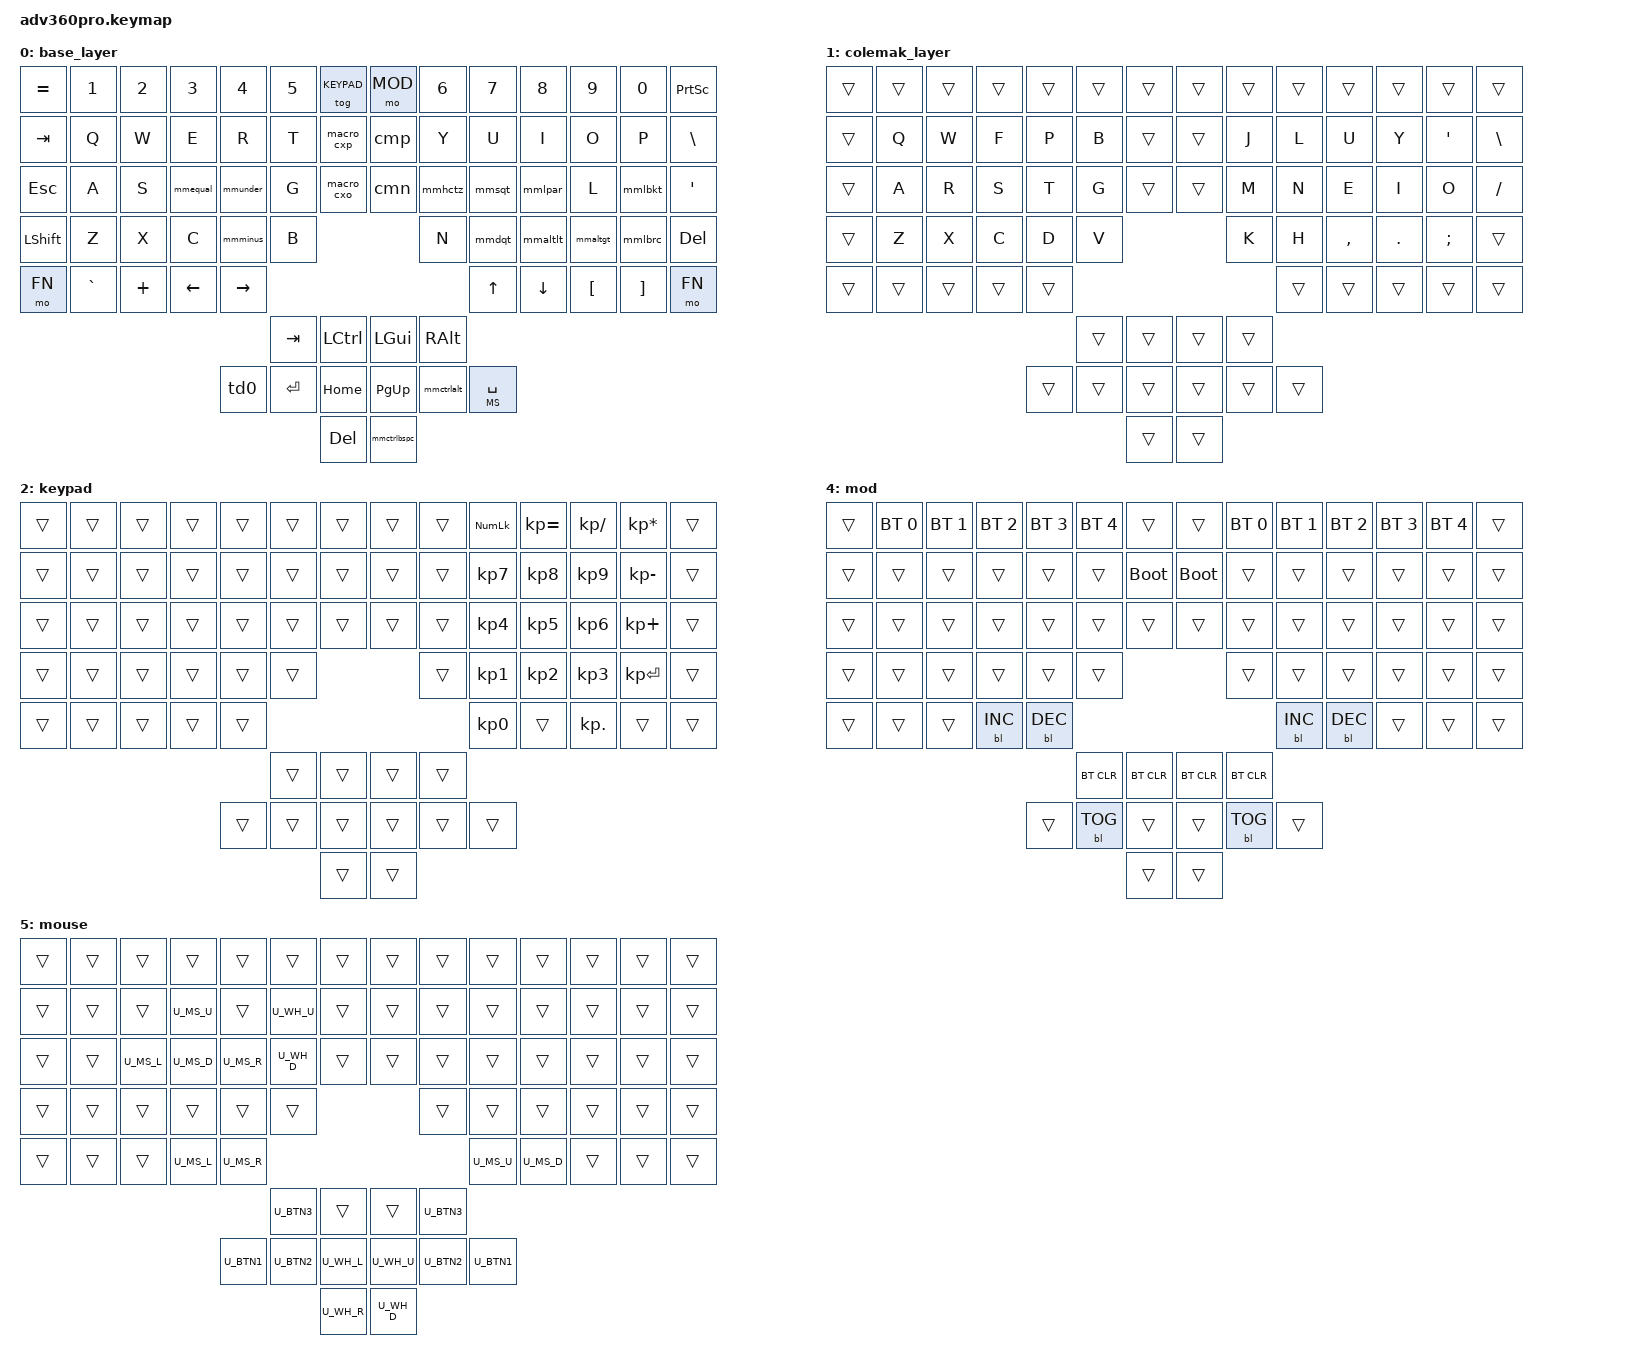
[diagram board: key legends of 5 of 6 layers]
#include <behaviors.dtsi>
#include <dt-bindings/zmk/keys.h>
#include <dt-bindings/zmk/bt.h>
#include <dt-bindings/zmk/outputs.h>
#include <dt-bindings/zmk/rgb.h>
#include <dt-bindings/zmk/backlight.h>

/* definitions for mouse layer */
#include "mouse.dtsi"

#define ___ &trans

#define QWERTY 0
#define COLEMAK 1
#define KEYPAD 2
#define FN 3
#define MOD 4
#define MS 5

#define MOD_MORPH_C(NAME, KEY, MOD_KEY) \
  mm##NAME: mm##NAME { \
    compatible = "zmk,behavior-mod-morph"; \
    label = #NAME; \
    #binding-cells = <0>; \
    bindings = <&kp KEY>, <&kp MOD_KEY>; \
    mods = <(MOD_LCTL|MOD_RCTL)>; \
  };

#define MOD_MORPH_S(NAME, KEY, MOD_KEY) \
  mm##NAME: mm##NAME { \
    compatible = "zmk,behavior-mod-morph"; \
    label = #NAME; \
    #binding-cells = <0>; \
    bindings = <&kp KEY>, <&kp MOD_KEY>; \
    mods = <(MOD_LSFT|MOD_RSFT)>; \
  };


/ {
      behaviors {
      #include "macros.dtsi"

      ht: hold_toggle {
	  compatible = "zmk,behavior-hold-tap";
	  label = "HOLD_TOGGLE";
          #binding-cells = <2>;
	  tapping-term-ms = <200>;
	  quick_tap_ms = <175>;
	  flavor = "tap-preferred";
	  bindings = <&mo>, <&kp>;
	};

        MOD_MORPH_S(ctrlbspc, BSPC, LC(BSPC))
	MOD_MORPH_S(ctrlalt, RCTL, LALT)
	MOD_MORPH_C(equal, D, EQUAL)
	MOD_MORPH_C(under, F, UNDERSCORE)
	MOD_MORPH_C(minus, V, MINUS)
	MOD_MORPH_C(sqt, J, SQT)
	MOD_MORPH_C(lpar, K, LPAR)
	MOD_MORPH_C(dqt, M, DQT)
	MOD_MORPH_C(lbkt, SEMI, LBKT)
	MOD_MORPH_C(lbrc, FSLH, LBRC)
	MOD_MORPH_C(altlt, COMMA, LA(LT))
	MOD_MORPH_C(altgt, DOT, LA(GT))
	MOD_MORPH_C(hctz, H, LC(Z))

    td0: tap_dance_0 {
	compatible = "zmk,behavior-tap-dance";
	label = "TAP_DANCE_0";
        #binding-cells = <0>;
	tapping-term-ms = <200>;
	bindings = <&kp LSHFT>, <&kp LC(SPACE)>;
      };
    };

    /* remove unused keys from layout and move thumb cluster to bottom */
    chosen {
        zmk,matrix_transform = &urobs_transform;
    };

    keymap {
        compatible = "zmk,keymap";

        base_layer {
            bindings = <
                &kp EQUAL &kp N1    &kp N2    &kp N3    &kp N4    &kp N5    &tog KEYPAD    &mo MOD   &kp N6    &kp N7    &kp N8    &kp N9    &kp N0    &kp PSCRN
                &kp TAB   &kp Q     &kp W     &kp E     &kp R     &kp T     &macro_cxp     &cmp   &kp Y     &kp U     &kp I     &kp O     &kp P     &kp BSLH
                &kp ESC   &kp A     &kp S     &mmequal  &mmunder  &kp G     &macro_cxo     &cmn   &mmhctz   &mmsqt    &mmlpar   &kp L     &mmlbkt   &kp SQT
                &kp LSHFT &kp Z     &kp X     &kp C     &mmminus  &kp B                              &kp N     &mmdqt    &mmaltlt  &mmaltgt  &mmlbrc   &kp DEL
                &mo FN    &kp GRAVE &kp PLUS  &kp LEFT  &kp RIGHT                                              &kp UP    &kp DOWN  &kp LBKT  &kp RBKT  &mo FN
                                                                  &kp TAB &kp LCTRL       &kp LGUI  &kp RALT
                                                        &td0  &kp ENTER   &kp HOME        &kp PG_UP &mmctrlalt &ht MS SPACE
                                                                           &kp DEL        &mmctrlbspc
            >;
        };

        colemak_layer {
            bindings = <
                ___       ___       ___       ___       ___       ___       ___            ___       ___       ___       ___       ___       ___       ___
                ___       &kp Q     &kp W     &kp F     &kp P     &kp B     ___            ___       &kp J     &kp L     &kp U     &kp Y     &kp SQT   &kp BSLH
                ___       &kp A     &kp R     &kp S     &kp T     &kp G     ___            ___       &kp M     &kp N     &kp E     &kp I     &kp O     &kp FSLH
                ___       &kp Z     &kp X     &kp C     &kp D     &kp V                              &kp K     &kp H     &kp COMMA &kp DOT   &kp SEMI  ___
                ___       ___       ___       ___       ___                                                    ___       ___       ___       ___       ___
                                                                  ___       ___            ___       ___
                                                        ___       ___       ___            ___       ___       ___
                                                                            ___            ___
            >;
        };

        keypad {
            bindings = <
                ___       ___       ___       ___       ___       ___       ___            ___       ___       &kp KP_NUM &kp KP_EQUAL &kp KP_DIVIDE &kp KP_MULTIPLY ___
                ___       ___       ___       ___       ___       ___       ___            ___       ___       &kp KP_N7  &kp KP_N8    &kp KP_N9     &kp KP_MINUS    ___
                ___       ___       ___       ___       ___       ___       ___            ___       ___       &kp KP_N4  &kp KP_N5    &kp KP_N6     &kp KP_PLUS     ___
                ___       ___       ___       ___       ___       ___                                ___       &kp KP_N1  &kp KP_N2    &kp KP_N3     &kp KP_ENTER    ___
                ___       ___       ___       ___       ___                                                    &kp KP_N0  ___          &kp KP_DOT    ___             ___
                                                                  ___       ___            ___       ___
                                                        ___       ___       ___            ___       ___       ___
                                                                            ___            ___
            >;
        };

        fn {
            bindings = <
                &kp F1    &kp F2    &kp F3    &kp F4    &kp F5    &kp F6    ___            ___       &kp F7    &kp F8    &kp F9    &kp F10   &kp F11   &kp F12
	      &kp LC(TAB) &kp Q     &kp W     &kp E     &kp R     &kp T     ___            ___       &kp Y     &kp U     &kp I     &kp O     &kp P     &kp BSLH
              &kp ESC     &kp A     &kp S     &kp LC(D) &kp LC(F) &kp G     ___            ___       &kp LC(H) &kp LC(J) &kp LC(K) &kp L     &kp LC(SEMI) &kp SQT
              &kp LSHFT   &kp Z     &kp X     &kp C     &kp LC(V) &kp B     ___            ___       &kp N     &kp LC(M) &kp LC(COMMA) &kp LC(DOT)  &kp LC(FSLH) &kp RSHFT
              &mo FN      &kp GRAVE &kp PLUS  &kp LEFT  &kp RIGHT                                              &kp UP    &kp DOWN  &kp LBKT  &kp RBKT  &mo FN
                                                                  ___       ___            ___       ___
                                                        ___       ___       ___            ___       ___       ___
                                                                            ___            ___
            >;
        };

        mod {
            bindings = <
                ___       &bt BT_SEL 0 &bt BT_SEL 1 &bt BT_SEL 2 &bt BT_SEL 3 &bt BT_SEL 4 ___              ___         &bt BT_SEL 0 &bt BT_SEL 1     &bt BT_SEL 2 &bt BT_SEL 3 &bt BT_SEL 4 ___
                ___       ___          ___          ___          ___          ___          &bootloader      &bootloader ___          ___              ___          ___          ___          ___
                ___       ___          ___          ___          ___          ___          ___              ___         ___          ___              ___          ___          ___          ___
                ___       ___          ___          ___          ___          ___                                       ___          ___              ___          ___          ___          ___
                ___       ___          ___          &bl BL_INC   &bl BL_DEC                                                          &bl BL_INC       &bl BL_DEC   ___          ___          ___
                                                                              &bt BT_CLR   &bt BT_CLR       &bt BT_CLR  &bt BT_CLR
                                                                 ___          &bl BL_TOG   ___              ___         &bl BL_TOG   ___
                                                                                           ___              ___
            >;
        };

        mouse {
            bindings = <
                ___       ___       ___       ___       ___       ___       ___            ___       ___       ___       ___       ___       ___       ___
                ___       ___       ___       U_MS_U    ___       U_WH_U    ___            ___       ___       ___       ___       ___       ___       ___
                ___       ___       U_MS_L    U_MS_D    U_MS_R    U_WH_D    ___            ___       ___       ___       ___       ___       ___       ___
                ___       ___       ___       ___       ___       ___                                ___       ___       ___       ___       ___       ___
                ___       ___       ___       U_MS_L    U_MS_R                                                 U_MS_U    U_MS_D    ___       ___       ___
                                                                  U_BTN3    ___            ___       U_BTN3
                                                        U_BTN1    U_BTN2    U_WH_L         U_WH_U    U_BTN2    U_BTN1
                                                                            U_WH_R         U_WH_D
            >;
        };

    };

};
